# STM32U5Gx register map
File version: 1.0
CPU: CM33 r0p1, little endian, MPU, FPU, 4 interrupt priority bits
Registers are 32-bit, read-write, reset 0x0 unless marked. A register's access mark holds for its fields unless they carry their own. Offsets are from the block's base; [hi:lo] are bit positions; {n}, {i} and the like mark numbered series; 'fields as' and 'values as' point back to an identical list.

## GFXTIM — GFXTIM register block
Base 0x40016400
Same registers: SEC_GFXTIM 0x50016400
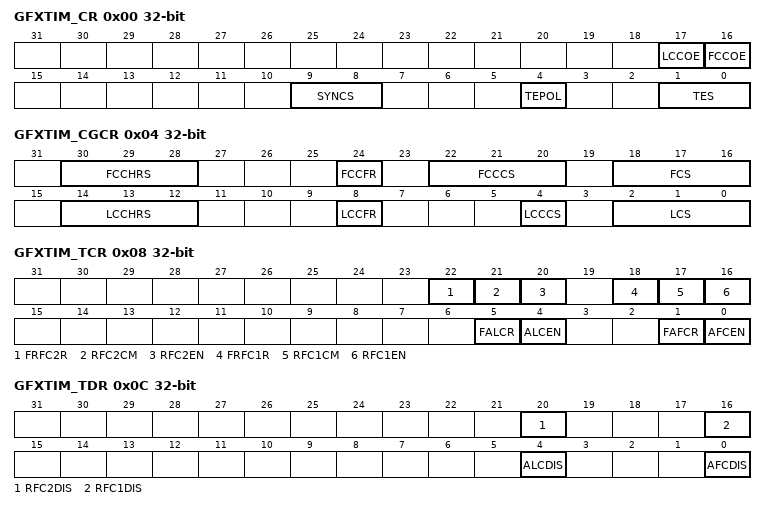
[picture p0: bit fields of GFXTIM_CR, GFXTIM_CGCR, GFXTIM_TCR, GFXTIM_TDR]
0x00 GFXTIM_CR — GFXTIM configuration register
  [17] LCCOE — line-clock calibration output enable This bit enables the line-clock output.
    0=line-clock output disabled; 1=line-clock output enabled
  [16] FCCOE — frame-clock calibration output enable This bit enables the frame-clock output.
    0=frame-clock output disabled; 1=frame-clock output enabled
  [9:8] SYNCS — synchronization source This field selects the synchronization signals (HSYNC and VSYNC) sources.
    {v}=gfxtim_hsync[{v}] and gfxtim_vsync[{v}] selected (v=0..3)
  [4] TEPOL — tearing--effect polarity This bit selects the tearing-effect polarity.
    0=tearing effect active on rising edge; 1=tearing effect active on falling edge
  [1:0] TES — tearing source This field selects the tearing-effect source.
    0=TE input pad selected; 1=gfxtim_ite selected; 2=HSYNC input selected by SYNCS[1:0]; 3=VSYNC input selected by SYNCS[1:0]
0x04 GFXTIM_CGCR access per field — GFXTIM clock generator configuration register
  [30:28] FCCHRS rw — frame- -clock counter hardware reload source This field configures the hardware reload source for the frame- -clock counter.
    0=no hardware reload; 1=line- -clock counter underflow; 2=HSYNC rising edge; 3=HSYNC falling edge; 4=VSYNC rising edge; 5=VSYNC falling edge; 6=TE rising edge; 7=TE falling edge
  [24] FCCFR wo — frame clock counter force reload This bit forces frame clock counter reload
    0=No effect; 1=frame clock counter reload forced
  [22:20] FCCCS rw — frame clock counter clock source This field configures the clock source for the frame clock counter.
    0=frame clock counter disabled; 1=line clock counter underflow; 2=HSYNC rising edge; 3=HSYNC falling edge; 4=VSYNC rising edge; 5=VSYNC falling edge; 6=TE rising edge; 7=TE falling edge
  [18:16] FCS rw — frame clock source This field configures the frame clock source
    0=line clock counter underflow; 1=frame clock counter underflow; 2=HSYNC rising edge; 3=HSYNC falling edge; 4=VSYNC rising edge; 5=VSYNC falling edge; 6=TE rising edge; 7=TE falling edge
  [14:12] LCCHRS rw — line clock counter hardware reload source This field configures the hardware reload source for the line clock counter.
    0=no hardware reload; 1=frame clock counter underflow; 2=HSYNC rising edge; 3=HSYNC falling edge; 4=VSYNC rising edge; 5=VSYNC falling edge; 6=TE rising edge; 7=TE falling edge
  [8] LCCFR wo — line clock counter force reload This bit forces line clock counter reload.
    0=no effect; 1=line clock counter reload forced
  [4] LCCCS rw — line clock counter clock source This bit configures the clock source for the line clock counter.
    0=line clock counter disabled; 1=system clock selected
  [2:0] LCS rw — line clock source This field configures the line clock source.
    values as FCS
0x08 GFXTIM_TCR access per field — GFXTIM timers configuration register
  [22] FRFC2R wo — force relative frame counter 2 reload This bit forces the reload of the relative frame counter 2.
    0=no effect; 1=relative frame counter 2 reload forced
  [21] RFC2CM rw — relative frame counter 2 continuous mode This bit enables the continuous mode of the relative frame counter 2.
    0=relative frame counter 2 is one shot; 1=relative frame counter 2 is in continuous mode
  [20] RFC2EN wo — relative frame counter 2 enable This bit enables the relative frame counter 2.
    0=no effect; 1=relative frame counter 2 enabled
  [18] FRFC1R wo — force relative frame counter 1 reload This bit forces the reload of the relative frame counter 1.
    0=no effect; 1=relative frame counter 1 reload forced
  [17] RFC1CM rw — relative frame counter 1 continuous mode This bit enables the continuous mode of the relative frame counter 1.
    0=relative frame counter 1 is one shot; 1=relative frame counter 1 is in continuous mode
  [16] RFC1EN wo — relative frame counter 1 enable This bit enables the relative frame counter 1.
    0=no effect; 1=relative frame counter enabled
  [5] FALCR wo — force absolute line counter reset This bit forces the reset of the absolute line counter.
    0=no effect; 1=absolute line counter reset forced
  [4] ALCEN wo — absolute line counter enable This bit enables the absolute line counter.
    0=no effect; 1=absolute line counter enabled
  [1] FAFCR wo — force absolute frame counter reset This bit forces the reset of the absolute frame counter.
    0=no effect; 1=absolute frame counter reset forced
  [0] AFCEN wo — absolute frame counter enable This bit enables the absolute frame counter.
    0=no effect; 1=absolute frame counter enabled
0x0C GFXTIM_TDR wo — GFXTIM timers disable register
  [20] RFC2DIS — relative frame counter 2 disable This bit disables the relative frame counter 2.
    0=no effect; 1=relative frame counter 2 disabled
  [16] RFC1DIS — relative frame counter 1 disable This bit disables the relative frame counter 1.
    0=no effect; 1=relative frame counter 1 disabled
  [4] ALCDIS — absolute line counter disable This bit disables the absolute line counter.
    0=no effect; 1=absolute line counter disabled
  [0] AFCDIS — absolute frame counter disable This bit disables the absolute frame counter.
    0=no effect; 1=absolute frame counter disabled
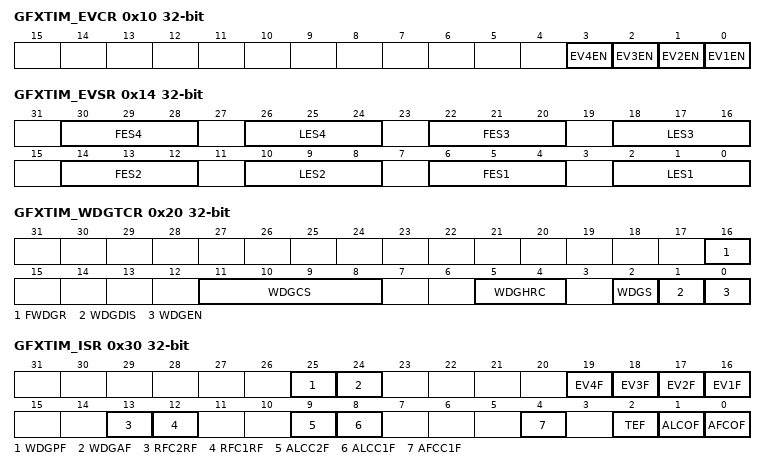
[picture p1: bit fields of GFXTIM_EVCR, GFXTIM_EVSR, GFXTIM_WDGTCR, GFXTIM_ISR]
0x10 GFXTIM_EVCR — GFXTIM events control register
  [n-1] EV{n}EN (n=1..4) — event {n} enable This bit enables the complex event {n} generation.
    0=event {n} generation disabled; 1=event {n} generation enabled
0x14 GFXTIM_EVSR — GFXTIM events selection register
  [8n-2:8n-4] FES{n} (n=1..4) — frame-event selection {n} This field defines the frame-event selection for complex event {n} generation. others: reserved
    0=no frame event; 1=absolute frame counter overflow; 2=absolute frame counter compare; 4=relative frame counter 1 reload; 5=relative frame counter 2 reload
  [26:24] LES4 — line-event selection 4 This field defines the line-event selection for complex event 4 generation. others: Reserved
    0=no line event; 1=absolute line counter overflow; 2=tearing effect; 4=absolute line counter 1 compare; 5=absolute line counter 2 compare
  [18:16] LES3 — line-event selection 3 This field defines the line-event selection for complex event 3 generation. others: reserved
    values as LES4
  [10:8] LES2 — line-event selection 2 This field defines the line-event selection for complex event 2 generation. others: reserved
    values as LES4
  [2:0] LES1 — line-event selection 1 This field defines the line-event selection for complex event 1 generation. others: reserved
    values as LES4
0x20 GFXTIM_WDGTCR access per field — GFXTIM watchdog timer configuration register
  [16] FWDGR wo — force watchdog reload This bit forces the reload of the graphic watchdog.
    0=no effect; 1=graphic watchdog reload forced
  [11:8] WDGCS rw — watchdog clock source This field selects the watchdog clock source. others: reserved
    0=line clock; 1=frame clock; 2=HSYNC rising edge; 3=HSYNC falling edge; 4=VSYNC rising edge; 5=VSYNC falling edge; 6=TE rising edge; 7=TE falling edge; {v}=event {v-7} (v=8..11)
  [5:4] WDGHRC rw — watchdog hardware reload configuration This field configures the watchdog hardware reload.
    0=watchdog hardware reload disabled; 1=watchdog reloaded a rising edge of gfxtim_wrld; 2=watchdog reloaded a falling edge of gfxtim_wrld
  [2] WDGS ro — watchdog status This bit returns the status of the graphic watchdog.
    0=graphic watchdog disabled; 1=graphic watchdog enabled
  [1] WDGDIS wo — watchdog disable This bit disables the graphic watchdog.
    0=no effect; 1=graphic watchdog disabled
  [0] WDGEN wo — watchdog enable This bit enables the graphic watchdog.
    0=no effect; 1=graphic watchdog enabled
0x30 GFXTIM_ISR ro — GFXTIM interrupt status register
  [25] WDGPF — watchdog pre-alarm flag This bit indicates that a graphic watchdog pre-alarm occurred.
    0=no graphic watchdog pre-alarm occurred; 1=a graphic watchdog pre-alarm occurred
  [24] WDGAF — watchdog alarm flag This bit indicates that a graphic watchdog alarm occurred.
    0=no graphic watchdog alarm occurred; 1=a graphic watchdog alarm occurred
  [19] EV4F — event 4 flag This bit indicates a complex event 4 occurred.
    0=no complex event 4 occurred; 1=a complex event 4 occurred
  [18] EV3F — event 3 flag This bit indicates a complex event 3 occurred.
    0=no complex event 3 occurred; 1=a complex event 3 occurred
  [17] EV2F — event 2 flag This bit indicates a complex event 2 occurred.
    0=no complex event 2 occurred; 1=a complex event 2 occurred
  [16] EV1F — event 1 flag This bit indicates a complex event 1 occurred.
    0=No complex event 1 occurred; 1=Complex event 1 occurred
  [13] RFC2RF — relative frame counter 2 reload flag This bit indicates relative frame counter 2 has been reloaded.
    0=no reload occurred on relative frame counter 2; 1=a reload on relative frame counter 2 occurred
  [12] RFC1RF — relative frame counter 1 reload flag This bit indicates relative frame counter 1 has been reloaded.
    0=no reload occurred on relative frame counter 1; 1=a reload on relative frame counter 1 occurred
  [9] ALCC2F — absolute line counter compare 2 flag This bit indicates match on compare 2 of the absolute line counter.
    0=no match occurred on compare 2 of the absolute line counter; 1=a match on compare 2 of the absolute line counter occurred
  [8] ALCC1F — absolute line counter compare 1 flag This bit indicates match on compare 1 of the absolute line counter.
    0=no match occurred on compare 1 of the absolute line counter; 1=a match on compare 1 of the absolute line counter occurred
  [4] AFCC1F — absolute frame counter compare 1 flag This bit indicates match on compare 1 of the absolute frame counter.
    0=no match occurred on compare 1 of the absolute frame counter; 1=a match on compare 1 of the absolute frame counter occurred
  [2] TEF — tearing-effect flag This bit indicates a tearing effect event occurred.
    0=no tearing effect occurred; 1=a tearing effect occurred
  [1] ALCOF — absolute line counter overflow flag This bit indicates an overflow occurred on the absolute line counter.
    0=no overflow occurred on the absolute line counter; 1=a overflow on the absolute line counter occurred
  [0] AFCOF — absolute frame counter overflow flag This bit indicates an overflow occurred on the absolute frame counter.
    0=no overflow occurred on the absolute frame counter; 1=a overflow on the absolute frame counter occurred
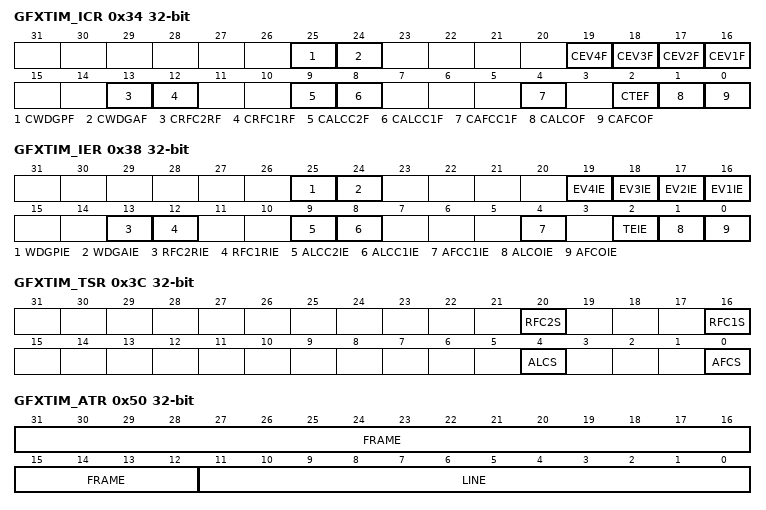
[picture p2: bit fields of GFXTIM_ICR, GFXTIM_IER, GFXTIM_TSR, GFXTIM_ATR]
0x34 GFXTIM_ICR wo — GFXTIM interrupt clear register
  [25] CWDGPF — clear watchdog pre-alarm flag This bit clears WDGPF in GXFXTIM_ISR.
    0=no effect; 1=WDGPF cleared
  [24] CWDGAF — clear watchdog alarm flag This bit clears WDGAF in GXFXTIM_ISR.
    0=no effect; 1=WDGAF cleared
  [19] CEV4F — clear event 4 flag This bit clears EV4F in GXFXTIM_ISR.
    0=no effect; 1=EV4F cleared
  [18] CEV3F — clear event 3 flag This bit clears EV3F in GXFXTIM_ISR.
    0=no effect; 1=EV3F cleared
  [17] CEV2F — clear event 2 flag This bit clears EV2F in GXFXTIM_ISR.
    0=no effect; 1=EV2F cleared
  [16] CEV1F — clear event 1 flag This bit EV1F in GXFXTIM_ISR.
    0=no effect; 1=EV1F cleared
  [13] CRFC2RF — clear relative frame counter 2 reload flag This bit clears RFC2RF in GXFXTIM_ISR.
    0=no effect; 1=RFC2RF cleared
  [12] CRFC1RF — clear relative frame counter 1 reload flag This bit clears RFC1RF in GXTIM_ISR.
    0=no effect; 1=RFC1RF cleared
  [9] CALCC2F — clear absolute line counter compare 2 flag This bit clears ALCC2F in GXTIM_ISR.
    0=no effect; 1=ALCC2F cleared
  [8] CALCC1F — clear absolute line counter compare 1 flag This bit clears ALCC1F in GXTIM_ISR.
    0=no effect; 1=ALCC1F cleared
  [4] CAFCC1F — clear absolute frame counter compare 1 flag This bit clears AFCC1F in GXTIM_ISR.
    0=no effect; 1=AFCC1F cleared
  [2] CTEF — clear tearing-effect flag This bit clears TEF in GXTIM_ISR.
    0=no effect; 1=TEF cleared
  [1] CALCOF — clear absolute line counter overflow flag This bit clears ALCOF in GXTIM_ISR.
    0=no effect; 1=ALCOF cleared
  [0] CAFCOF — clear absolute frame counter overflow flag This bit clears AFCOF in GXTIM_ISR.
    0=no effect; 1=AFCOF cleared
0x38 GFXTIM_IER — GFXTIM interrupt enable register
  [25] WDGPIE — watchdog pre-alarm interrupt enable This bit enables the watchdog pre-alarm interrupt generation.
    0=watchdog pre-alarm interrupt disabled; 1=watchdog pre-alarm interrupt enabled
  [24] WDGAIE — watchdog alarm interrupt enable This bit enables the watchdog alarm interrupt generation.
    0=watchdog alarm interrupt disabled; 1=watchdog alarm interrupt enabled
  [n+15] EV{n}IE (n=1..4) — event {n} interrupt enable This bit enables the complex event {n} interrupt generation.
    0=event {n} interrupt disabled; 1=event {n} interrupt enabled
  [13] RFC2RIE — relative frame counter 2 reload interrupt enable This bit enables the relative frame counter 2 reload interrupt generation.
    0=relative frame counter 2 reload interrupt disabled; 1=relative frame counter 2 reload interrupt enabled
  [12] RFC1RIE — relative frame counter 1 reload interrupt enable This bit enables the relative frame counter 1 reload interrupt generation.
    0=relative frame counter 1 reload interrupt disabled; 1=relative frame counter 1 reload interrupt enabled
  [9] ALCC2IE — absolute line counter compare 2 interrupt enable This bit enables the absolute line counter compare 2 interrupt generation.
    0=absolute line counter compare 2 interrupt disabled; 1=absolute line counter compare 2 interrupt enabled
  [8] ALCC1IE — absolute line counter compare 1 interrupt enable This bit enables the absolute line counter compare 1 interrupt generation.
    0=absolute line counter compare 1 interrupt disabled; 1=absolute line counter compare 1 interrupt enabled
  [4] AFCC1IE — absolute frame counter compare 1 interrupt enable This bit enables the absolute frame counter compare interrupt generation.
    0=absolute frame counter compare 1 interrupt disabled; 1=absolute frame counter compare 1 interrupt enabled
  [2] TEIE — tearing-effect interrupt enable This bit enables the Tearing Effect interrupt generation.
    0=tearing-effect interrupt disabled; 1=tearing-effect interrupt enabled
  [1] ALCOIE — absolute line counter overflow interrupt enable This bit enables the absolute line counter overflow interrupt generation.
    0=absolute line counter overflow interrupt disabled; 1=absolute line counter overflow interrupt enabled
  [0] AFCOIE — absolute frame counter overflow interrupt enable This bit enables the absolute frame counter overflow interrupt generation.
    0=absolute frame counter overflow interrupt disabled; 1=absolute frame counter overflow interrupt enabled
0x3C GFXTIM_TSR ro — GFXTIM timers status register
  [20] RFC2S — relative frame counter 2 status This bit returns the status of the relative frame counter 2.
    0=relative frame counter 2 disabled; 1=relative frame counter 2 enabled
  [16] RFC1S — relative frame counter 1 status This bit returns the status of the relative frame counter 1.
    0=relative frame counter 1 disabled; 1=relative frame counter 1 enabled
  [4] ALCS — absolute line counter status This bit returns the status of the absolute line counter.
    0=absolute line counter disabled; 1=absolute line counter enabled
  [0] AFCS — absolute frame counter status This bit returns the status of the absolute frame counter.
    0=absolute frame counter disabled; 1=absolute frame counter enabled
0x40 GFXTIM_LCCRR — GFXTIM line clock counter reload register
  [21:0] RELOAD — reload value Reload value of the line clock counter.
0x44 GFXTIM_FCCRR — GFXTIM frame clock counter reload register
  [11:0] RELOAD — reload value Reload value of the frame clock counter.
0x50 GFXTIM_ATR ro — GFXTIM absolute time register
  [31:12] FRAME — fame number Current value of the absolute frame counter.
  [11:0] LINE — line number Current value of the absolute line counter.
0x54 GFXTIM_AFCR — GFXTIM absolute frame counter register
  [19:0] FRAME — frame number Current value of the absolute frame counter. Note: This field can only be written when the absolute frame counter is disabled.
0x58 GFXTIM_ALCR — GFXTIM absolute line counter register
  [11:0] LINE — line number Current value of the absolute line counter. Note: This field can only be written when the absolute frame counter is disabled.
0x60 GFXTIM_AFCC1R — GFXTIM absolute frame counter compare 1 register
  [19:0] FRAME — frame number Compare 1 value for the absolute frame counter.
0x70 GFXTIM_ALCC1R — GFXTIM absolute line counter compare 1 register
  [11:0] LINE — line number Compare value 1 for the absolute line counter.
0x74 GFXTIM_ALCC2R — GFXTIM absolute line counter compare 2 register
  [11:0] LINE — line number Compare value 2 for the absolute line counter.
0x80 GFXTIM_RFC1R ro — GFXTIM relative frame counter 1 register
  [11:0] FRAME — frame number Current value of the relative frame counter 1.
0x84 GFXTIM_RFC1RR — GFXTIM relative frame counter 1 reload register
  [11:0] FRAME — frame reload value Reload value for the relative frame counter 1.
0x88 GFXTIM_RFC2R ro — GFXTIM relative frame counter 2 register
  [11:0] FRAME — frame number Current value of the relative frame counter 2.
0x8C GFXTIM_RFC2RR — GFXTIM relative frame counter 2 reload register
  [11:0] FRAME — frame reload value Reload value for the relative frame counter 2.
0xA0 GFXTIM_WDGCR ro — GFXTIM watchdog counter register
  [15:0] VALUE — value Current value of the watchdog counter.
0xA4 GFXTIM_WDGRR — GFXTIM watchdog reload register
  [15:0] RELOAD — reload value Reload value of the watchdog counter.
0xA8 GFXTIM_WDGPAR — GFXTIM watchdog pre-alarm register
  [15:0] PREALARM — pre-alarm value Pre-alarm value of the watchdog counter.
